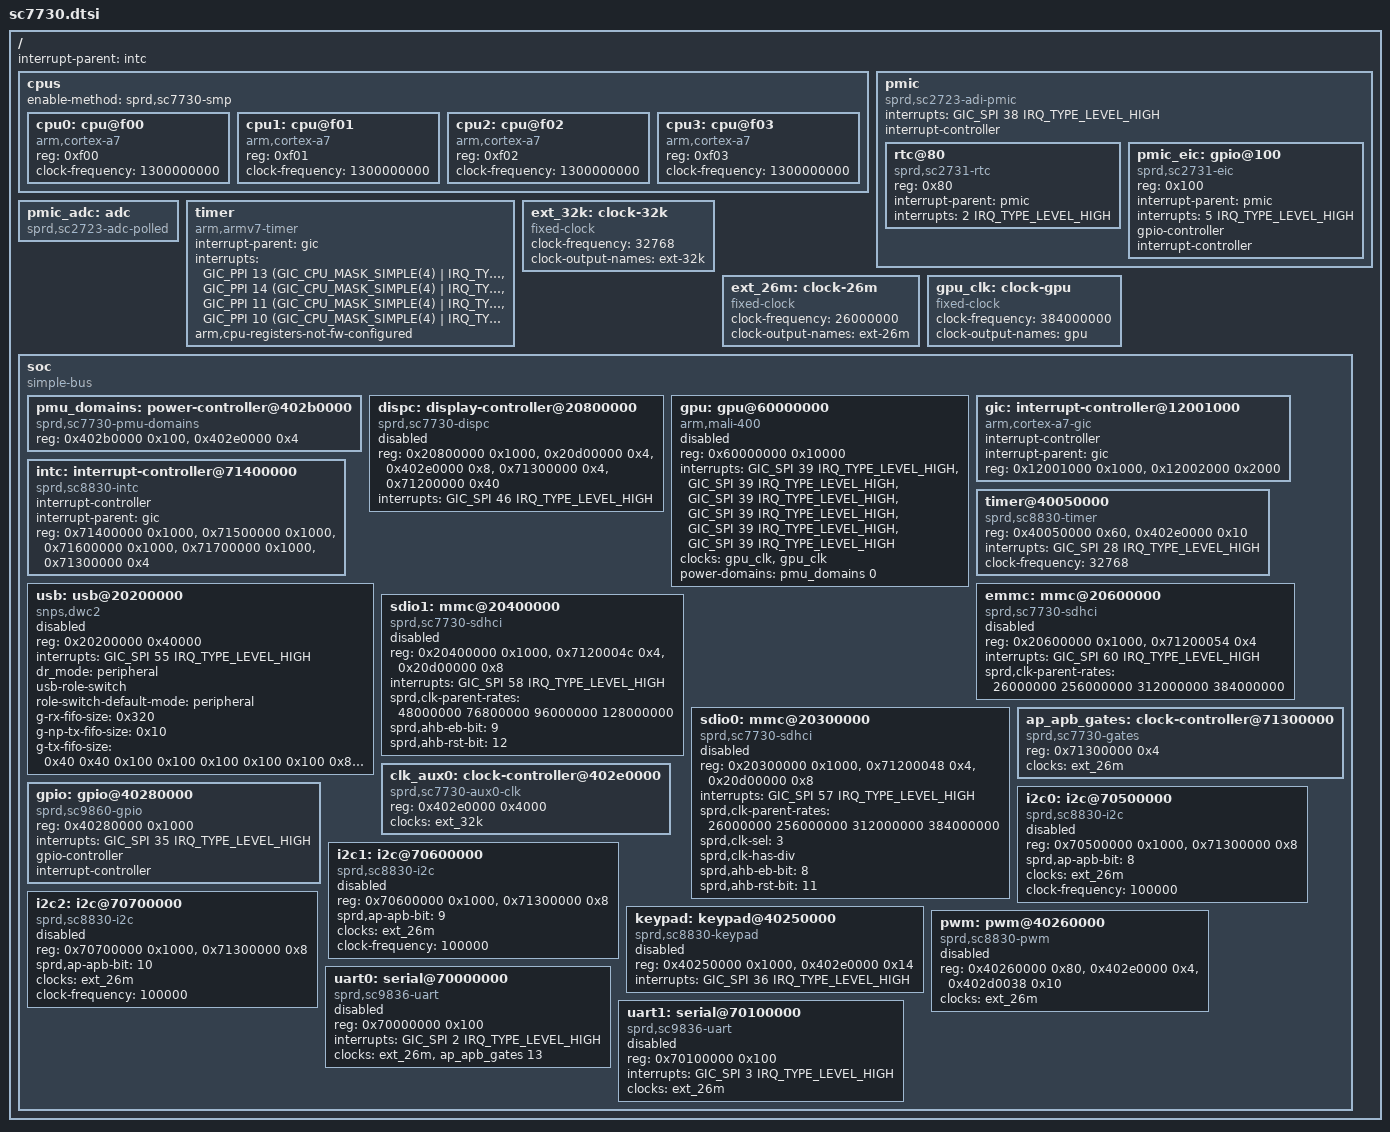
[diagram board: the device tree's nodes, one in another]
// SPDX-License-Identifier: GPL-2.0
/*
 * Spreadtrum SC7730 ("scx35", "shark") SoC, 4x Cortex-A7, Mali-400 MP2.
 *
 * Addresses are physical and come from the vendor 3.10 kernel
 * (arch/arm/mach-sc/include/mach/__hardware-sc8830.h). The vendor
 * device tree uses static virtual mappings (0xf5xxxxxx), translated here.
 *
 * Only what is needed for a first mainline boot is described: one CPU,
 * GIC, timer, UART. Everything else is still set up by the bootloader.
 */

#include <dt-bindings/interrupt-controller/arm-gic.h>

/ {
	#address-cells = <1>;
	#size-cells = <1>;
	interrupt-parent = <&intc>;

	cpus {
		#address-cells = <1>;
		#size-cells = <0>;
		/* boot ROM pen + PMU power domains, mach-sprd/platsmp.c */
		enable-method = "sprd,sc7730-smp";

		cpu0: cpu@f00 {
			device_type = "cpu";
			compatible = "arm,cortex-a7";
			reg = <0xf00>;
			clock-frequency = <1300000000>;
		};

		cpu1: cpu@f01 {
			device_type = "cpu";
			compatible = "arm,cortex-a7";
			reg = <0xf01>;
			clock-frequency = <1300000000>;
		};

		cpu2: cpu@f02 {
			device_type = "cpu";
			compatible = "arm,cortex-a7";
			reg = <0xf02>;
			clock-frequency = <1300000000>;
		};

		cpu3: cpu@f03 {
			device_type = "cpu";
			compatible = "arm,cortex-a7";
			reg = <0xf03>;
			clock-frequency = <1300000000>;
		};
	};

	/*
	 * SC2723 companion PMIC behind the ADI bus, as a regmap with its
	 * interrupt controller (mach-sprd/sc2723-pmic.c) until spi-sprd-adi
	 * and the sc27xx MFD know it. Children use the mainline drivers.
	 */
	pmic: pmic {
		compatible = "sprd,sc2723-adi-pmic";
		interrupts = <GIC_SPI 38 IRQ_TYPE_LEVEL_HIGH>;
		interrupt-controller;
		#interrupt-cells = <2>;
		#address-cells = <1>;
		#size-cells = <0>;

		rtc@80 {
			compatible = "sprd,sc2731-rtc";
			reg = <0x80>;
			interrupt-parent = <&pmic>;
			interrupts = <2 IRQ_TYPE_LEVEL_HIGH>;
		};

		pmic_eic: gpio@100 {
			compatible = "sprd,sc2731-eic";
			reg = <0x100>;
			interrupt-parent = <&pmic>;
			interrupts = <5 IRQ_TYPE_LEVEL_HIGH>;
			gpio-controller;
			#gpio-cells = <2>;
			interrupt-controller;
			#interrupt-cells = <2>;
		};
	};

	/* SC2723 auxiliary ADC (mach-sprd/sc2723-adc.c), raw counts */
	pmic_adc: adc {
		compatible = "sprd,sc2723-adc-polled";
		#io-channel-cells = <1>;
	};

	/*
	 * Counts the CoreSight timestamp generator TS1 at 26 MHz, which
	 * mach-sprd/sc7730.c starts (and sets CNTFRQ for). The kernel runs in
	 * the Secure world with a random CNTVOFF: secure physical timer, and
	 * no virtual counter for user space.
	 */
	timer {
		compatible = "arm,armv7-timer";
		interrupt-parent = <&gic>;
		interrupts = <GIC_PPI 13 (GIC_CPU_MASK_SIMPLE(4) | IRQ_TYPE_LEVEL_LOW)>,
			     <GIC_PPI 14 (GIC_CPU_MASK_SIMPLE(4) | IRQ_TYPE_LEVEL_LOW)>,
			     <GIC_PPI 11 (GIC_CPU_MASK_SIMPLE(4) | IRQ_TYPE_LEVEL_LOW)>,
			     <GIC_PPI 10 (GIC_CPU_MASK_SIMPLE(4) | IRQ_TYPE_LEVEL_LOW)>;
		arm,cpu-registers-not-fw-configured;
	};

	ext_32k: clock-32k {
		compatible = "fixed-clock";
		#clock-cells = <0>;
		clock-frequency = <32768>;
		clock-output-names = "ext-32k";
	};

	ext_26m: clock-26m {
		compatible = "fixed-clock";
		#clock-cells = <0>;
		clock-frequency = <26000000>;
		clock-output-names = "ext-26m";
	};

	/*
	 * Mali core clock: mach-sprd/pm-domains.c selects 384 MHz (TDPLL / 2)
	 * in the GPU's own clock mux on every power-up of the GPU domain.
	 */
	gpu_clk: clock-gpu {
		compatible = "fixed-clock";
		#clock-cells = <0>;
		clock-frequency = <384000000>;
		clock-output-names = "gpu";
	};

	soc {
		compatible = "simple-bus";
		#address-cells = <1>;
		#size-cells = <1>;
		ranges;

		/* GPU_TOP and MM_TOP power domains (mach-sprd/pm-domains.c) */
		pmu_domains: power-controller@402b0000 {
			compatible = "sprd,sc7730-pmu-domains";
			reg = <0x402b0000 0x100>, <0x402e0000 0x4>;
			reg-names = "pmu", "aon-apb";
			#power-domain-cells = <1>;
		};

		/*
		 * Display controller. Its clocks and gates (AP_AHB EB bit 1,
		 * AON_APB EB1 bit 11, AP_APB EB bit 18, AP_CLK 0x2c-0x34) are
		 * set up by the bootloader and only read by the driver.
		 */
		dispc: display-controller@20800000 {
			compatible = "sprd,sc7730-dispc";
			reg = <0x20800000 0x1000>, <0x20d00000 0x4>,
			      <0x402e0000 0x8>, <0x71300000 0x4>,
			      <0x71200000 0x40>;
			reg-names = "dispc", "ap-ahb", "aon-apb", "ap-apb",
				    "ap-clk";
			interrupts = <GIC_SPI 46 IRQ_TYPE_LEVEL_HIGH>;
			status = "disabled";
		};

		/*
		 * Mali-400 MP2, all units on one interrupt line. Its AXI enable
		 * (AON_APB EB0 bit 27) is switched with the power domain.
		 */
		gpu: gpu@60000000 {
			compatible = "arm,mali-400";
			reg = <0x60000000 0x10000>;
			interrupts = <GIC_SPI 39 IRQ_TYPE_LEVEL_HIGH>,
				     <GIC_SPI 39 IRQ_TYPE_LEVEL_HIGH>,
				     <GIC_SPI 39 IRQ_TYPE_LEVEL_HIGH>,
				     <GIC_SPI 39 IRQ_TYPE_LEVEL_HIGH>,
				     <GIC_SPI 39 IRQ_TYPE_LEVEL_HIGH>,
				     <GIC_SPI 39 IRQ_TYPE_LEVEL_HIGH>;
			interrupt-names = "gp", "gpmmu", "pp0", "ppmmu0",
					  "pp1", "ppmmu1";
			clocks = <&gpu_clk>, <&gpu_clk>;
			clock-names = "bus", "core";
			power-domains = <&pmu_domains 0>;
			status = "disabled";
		};

		gic: interrupt-controller@12001000 {
			compatible = "arm,cortex-a7-gic";
			#interrupt-cells = <3>;
			interrupt-controller;
			interrupt-parent = <&gic>;
			reg = <0x12001000 0x1000>,
			      <0x12002000 0x2000>;
		};

		/*
		 * Wake-up gates in front of the GIC: an idle CPU only wakes
		 * for interrupts enabled here. All SPIs go through it.
		 */
		intc: interrupt-controller@71400000 {
			compatible = "sprd,sc8830-intc";
			#interrupt-cells = <3>;
			interrupt-controller;
			interrupt-parent = <&gic>;
			reg = <0x71400000 0x1000>, <0x71500000 0x1000>,
			      <0x71600000 0x1000>, <0x71700000 0x1000>,
			      <0x71300000 0x4>;		/* AP APB clock gates */
		};

		timer@40050000 {
			compatible = "sprd,sc8830-timer";
			reg = <0x40050000 0x60>,	/* AON timer block */
			      <0x402e0000 0x10>;	/* AON APB clock gates */
			reg-names = "timer", "aon-apb";
			interrupts = <GIC_SPI 28 IRQ_TYPE_LEVEL_HIGH>;
			clock-frequency = <32768>;
		};

		/*
		 * Synopsys DWC OTG ("sprd,usb" in the vendor tree). PHY power,
		 * clock and resets are still done by mach-sprd/usb-bringup.c.
		 * No VBUS sensing wired to the core: the role switch override
		 * forces the B-session valid, like the vendor driver does.
		 *
		 * FIFOs (32-bit words) as in the vendor dwc_otg for SCX35, only
		 * TX FIFO 15 trimmed so everything fits the 3598-word SPRAM.
		 * TX FIFOs 1 and 2 are only 0x40 deep, too small for HS bulk;
		 * the dwc2 defaults left no FIFO for a 512-byte bulk IN endpoint.
		 */
		usb: usb@20200000 {
			compatible = "snps,dwc2";
			reg = <0x20200000 0x40000>;
			interrupts = <GIC_SPI 55 IRQ_TYPE_LEVEL_HIGH>;
			dr_mode = "peripheral";
			usb-role-switch;
			role-switch-default-mode = "peripheral";
			g-rx-fifo-size = <0x320>;
			g-np-tx-fifo-size = <0x10>;
			g-tx-fifo-size = <0x40 0x40 0x100 0x100 0x100 0x100 0x100
					  0x80 0x80 0x80 0x80 0x80 0x80 0x80 0x100>;
			status = "disabled";
		};

		/*
		 * eMMC host (vendor: sdhci@f511c000, "sprd,sdhci-shark", id 3).
		 * Base clock: AP_CLK_EMMC_CFG mux, 26/256/312/384 MHz. Gate
		 * (AP_AHB_EB bit 11), pinmux and card power come from the
		 * bootloader for now.
		 */
		emmc: mmc@20600000 {
			compatible = "sprd,sc7730-sdhci";
			reg = <0x20600000 0x1000>, <0x71200054 0x4>;
			reg-names = "sdhci", "clk-cfg";
			interrupts = <GIC_SPI 60 IRQ_TYPE_LEVEL_HIGH>;
			sprd,clk-parent-rates = <26000000 256000000 312000000 384000000>;
			status = "disabled";
		};

		/*
		 * SDIO1, the WLAN slot. Unlike the eMMC host it is left gated by
		 * the bootloader: AP_AHB EB bit 9, soft reset bit 12. Base clock
		 * mux AP_CLK_SDIO1_CFG (48/76.8/96/128 MHz, bootloader: 48).
		 */
		sdio1: mmc@20400000 {
			compatible = "sprd,sc7730-sdhci";
			reg = <0x20400000 0x1000>, <0x7120004c 0x4>,
			      <0x20d00000 0x8>;
			reg-names = "sdhci", "clk-cfg", "ap-ahb";
			interrupts = <GIC_SPI 58 IRQ_TYPE_LEVEL_HIGH>;
			sprd,clk-parent-rates = <48000000 76800000 96000000 128000000>;
			sprd,ahb-eb-bit = <9>;
			sprd,ahb-rst-bit = <12>;
			status = "disabled";
		};

		/*
		 * SDIO0, the microSD slot (vendor id 0). Gated by the
		 * bootloader: AP_AHB EB bit 8, soft reset bit 11. Base clock
		 * AP_CLK_SDIO0_CFG: mux bits 1:0, divider bits 10:8.
		 */
		sdio0: mmc@20300000 {
			compatible = "sprd,sc7730-sdhci";
			reg = <0x20300000 0x1000>, <0x71200048 0x4>,
			      <0x20d00000 0x8>;
			reg-names = "sdhci", "clk-cfg", "ap-ahb";
			interrupts = <GIC_SPI 57 IRQ_TYPE_LEVEL_HIGH>;
			sprd,clk-parent-rates = <26000000 256000000 312000000 384000000>;
			sprd,clk-sel = <3>;	/* 384 MHz like the vendor */
			sprd,clk-has-div;
			sprd,ahb-eb-bit = <8>;
			sprd,ahb-rst-bit = <11>;
			status = "disabled";
		};

		/* AP APB enable bits as gate clocks (mach-sprd/clk-gates.c) */
		ap_apb_gates: clock-controller@71300000 {
			compatible = "sprd,sc7730-gates";
			reg = <0x71300000 0x4>;
			clocks = <&ext_26m>;
			#clock-cells = <1>;
		};

		/* CLK_AUX0 pad, 32 kHz (mach-sprd/clk-aux0.c) */
		clk_aux0: clock-controller@402e0000 {
			compatible = "sprd,sc7730-aux0-clk";
			reg = <0x402e0000 0x4000>;
			clocks = <&ext_32k>;
			#clock-cells = <0>;
		};

		/* Same register layout as the SC9860 "d-gpio" block */
		gpio: gpio@40280000 {
			compatible = "sprd,sc9860-gpio";
			reg = <0x40280000 0x1000>;
			interrupts = <GIC_SPI 35 IRQ_TYPE_LEVEL_HIGH>;
			gpio-controller;
			#gpio-cells = <2>;
			interrupt-controller;
			#interrupt-cells = <2>;
		};

		/* I2C0, the camera sensors. Gate and reset: bit 8 in AP_APB. */
		i2c0: i2c@70500000 {
			compatible = "sprd,sc8830-i2c";
			reg = <0x70500000 0x1000>, <0x71300000 0x8>;
			reg-names = "i2c", "ap-apb";
			sprd,ap-apb-bit = <8>;
			clocks = <&ext_26m>;
			clock-frequency = <100000>;
			#address-cells = <1>;
			#size-cells = <0>;
			status = "disabled";
		};

		/*
		 * I2C1. Source clock 26 MHz (AP_CLK_I2C1_CFG mux 0, as the
		 * vendor leaves it); gate and reset are bit 9 in AP_APB.
		 */
		i2c1: i2c@70600000 {
			compatible = "sprd,sc8830-i2c";
			reg = <0x70600000 0x1000>, <0x71300000 0x8>;
			reg-names = "i2c", "ap-apb";
			sprd,ap-apb-bit = <9>;
			clocks = <&ext_26m>;
			clock-frequency = <100000>;
			#address-cells = <1>;
			#size-cells = <0>;
			status = "disabled";
		};

		/* I2C2, sensors on the gtelwifi. Gate and reset: bit 10. */
		i2c2: i2c@70700000 {
			compatible = "sprd,sc8830-i2c";
			reg = <0x70700000 0x1000>, <0x71300000 0x8>;
			reg-names = "i2c", "ap-apb";
			sprd,ap-apb-bit = <10>;
			clocks = <&ext_26m>;
			clock-frequency = <100000>;
			#address-cells = <1>;
			#size-cells = <0>;
			status = "disabled";
		};

		/*
		 * Keypad matrix (vendor: sprd,sci-keypad). Clock gates (AON_APB
		 * EB0 bit 8, RTC_EB bit 1) and soft reset (RST0 bit 8) are set
		 * up by the driver through "aon-apb".
		 */
		keypad: keypad@40250000 {
			compatible = "sprd,sc8830-keypad";
			reg = <0x40250000 0x1000>, <0x402e0000 0x14>;
			reg-names = "kpd", "aon-apb";
			interrupts = <GIC_SPI 36 IRQ_TYPE_LEVEL_HIGH>;
			status = "disabled";
		};

		/*
		 * Always-on PWM, four channels. Gates are AON APB EB0 bits
		 * 4..7, clock selects one register per channel at 0x402d0038.
		 */
		pwm: pwm@40260000 {
			compatible = "sprd,sc8830-pwm";
			reg = <0x40260000 0x80>, <0x402e0000 0x4>,
			      <0x402d0038 0x10>;
			reg-names = "pwm", "aon-apb", "clk-sel";
			clocks = <&ext_26m>;
			#pwm-cells = <2>;
			status = "disabled";
		};

		/* Bluetooth on the gtelwifi; 26 MHz (vendor: 48 MHz) */
		uart0: serial@70000000 {
			compatible = "sprd,sc9836-uart";
			reg = <0x70000000 0x100>;
			interrupts = <GIC_SPI 2 IRQ_TYPE_LEVEL_HIGH>;
			clocks = <&ext_26m>, <&ap_apb_gates 13>;
			clock-names = "uart", "enable";
			status = "disabled";
		};

		uart1: serial@70100000 {
			compatible = "sprd,sc9836-uart";
			reg = <0x70100000 0x100>;
			interrupts = <GIC_SPI 3 IRQ_TYPE_LEVEL_HIGH>;
			clocks = <&ext_26m>;
			clock-names = "uart";
			status = "disabled";
		};
	};
};
